AUTOSAR XML (schema 4-0-3)
package /ComponentTypes
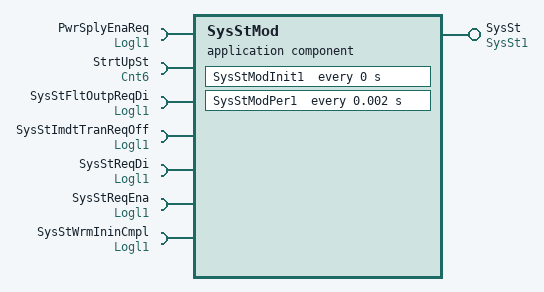
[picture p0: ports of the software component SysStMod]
  application sw component type SysStMod
    provide port SysSt: nonqueued-sender-com-spec{data-element=Val, init-value=3}, provided-interface=SysSt1
    7 x require port:
      PwrSplyEnaReq: nonqueued-receiver-com-spec{data-element=Logl, filter=data-filter-type=ALWAYS, init-value=0}, required-interface=Logl1
      StrtUpSt: nonqueued-receiver-com-spec{data-element=Val, filter=data-filter-type=ALWAYS, init-value=0}, required-interface=Cnt6
      SysStFltOutpReqDi: nonqueued-receiver-com-spec{data-element=Logl, filter=data-filter-type=ALWAYS, init-value=0}, required-interface=Logl1
      SysStImdtTranReqOff: nonqueued-receiver-com-spec{data-element=Logl, filter=data-filter-type=ALWAYS, init-value=0}, required-interface=Logl1
      SysStReqDi: nonqueued-receiver-com-spec{data-element=Logl, filter=data-filter-type=ALWAYS, init-value=0}, required-interface=Logl1
      SysStReqEna: nonqueued-receiver-com-spec{data-element=Logl, filter=data-filter-type=ALWAYS, init-value=0}, required-interface=Logl1
      SysStWrmIninCmpl: nonqueued-receiver-com-spec{data-element=Logl, filter=data-filter-type=ALWAYS, init-value=0}, required-interface=Logl1
    behavior SysStMod_InternalBehavior: data-type-mapping=Nexteer
      ar-typed-per-instance-memorys:
        data dSysStModTranVect: sw-calibration-access=READ-ONLY, type=Cnt4
        data SysStModPrevSysSt: sw-calibration-access=READ-ONLY, type=SysSt1
      timing event SysStMod_InitEvent: start-on-event=SysStModInit1, period=0
      timing event TMT_SysStModPer1: start-on-event=SysStModPer1, period=0.002
      runnable SysStModInit1
      runnable SysStModPer1
        data-receive-point-by-arguments:
          7 x access:
            REC_PwrSplyEnReq_Logl: accessed-variable=PwrSplyEnaReq.Logl
            REC_StrtUpSt_Val: accessed-variable=StrtUpSt.Val
            REC_SysStFltOutpReqDi_Logl: accessed-variable=SysStFltOutpReqDi.Logl
            REC_SysStImdtTranReqOff_Logl: accessed-variable=SysStImdtTranReqOff.Logl
            REC_SysStReqDi_Logl: accessed-variable=SysStReqDi.Logl
            REC_SysStReqEn_Logl: accessed-variable=SysStReqEna.Logl
            REC_SysStWrmIninCmpl_Logl: accessed-variable=SysStWrmIninCmpl.Logl
        data-send-points:
          access SEND_SysSt_Val_1: accessed-variable=SysSt.Val
  swc implementation SysStMod_Implementation: behavior=SysStMod_InternalBehavior
    code-descriptors:
      code Default: artifact-descriptors=autosar-engineering-object={short-label=Default, category=SWSRC}
